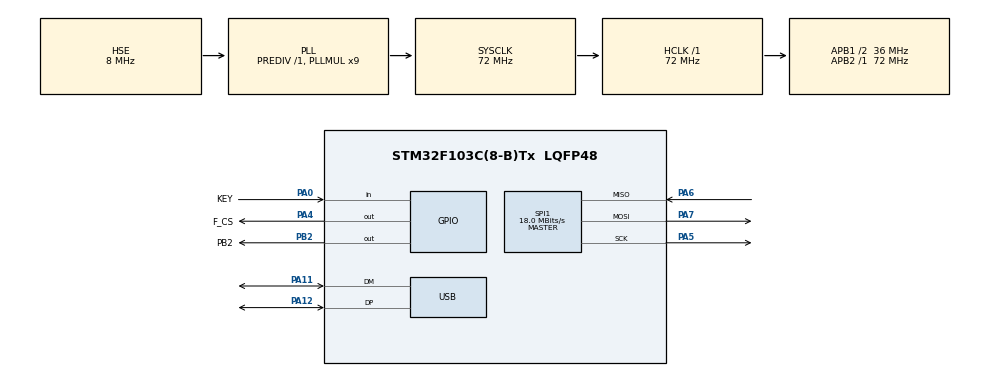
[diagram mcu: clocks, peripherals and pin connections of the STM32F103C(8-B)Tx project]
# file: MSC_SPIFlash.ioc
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Mcu.Family=STM32F1
Mcu.Name=STM32F103C(8-B)Tx
Mcu.Package=LQFP48
NVIC.PriorityGroup=NVIC_PRIORITYGROUP_4
NVIC.SPI1_IRQn=true\:0\:0\:false\:false\:true\:true\:true
NVIC.USB_HP_CAN1_TX_IRQn=true\:0\:0\:false\:false\:true\:true\:true
NVIC.USB_LP_CAN1_RX0_IRQn=true\:0\:0\:false\:false\:true\:false\:true
PA0-WKUP.GPIO_Label=KEY
PA0-WKUP.GPIO_PuPd=GPIO_PULLDOWN
PA0-WKUP.Signal=GPIO_Input
PA11.Mode=Device
PA11.Signal=USB_DM
PA12.Mode=Device
PA12.Signal=USB_DP
PA13.Mode=Serial_Wire
PA13.Signal=SYS_JTMS-SWDIO
PA14.Mode=Serial_Wire
PA14.Signal=SYS_JTCK-SWCLK
PA4.GPIO_Label=F_CS
PA4.GPIO_Speed=GPIO_SPEED_FREQ_HIGH
PA4.PinState=GPIO_PIN_SET
PA4.Signal=GPIO_Output
PA5.Mode=Full_Duplex_Master
PA5.Signal=SPI1_SCK
PA6.Mode=Full_Duplex_Master
PA6.Signal=SPI1_MISO
PA7.Mode=Full_Duplex_Master
PA7.Signal=SPI1_MOSI
PB2.GPIO_Label=PB2
PB2.Signal=GPIO_Output
PD0-OSC_IN.Mode=HSE-External-Oscillator
PD0-OSC_IN.Signal=RCC_OSC_IN
PD1-OSC_OUT.Mode=HSE-External-Oscillator
PD1-OSC_OUT.Signal=RCC_OSC_OUT
ProjectManager.HeapSize=0x800
ProjectManager.StackSize=0x400
ProjectManager.TargetToolchain=MDK-ARM V5.27
RCC.AHBFreq_Value=72000000
RCC.APB1CLKDivider=RCC_HCLK_DIV2
RCC.APB1Freq_Value=36000000
RCC.APB1TimFreq_Value=72000000
RCC.APB2Freq_Value=72000000
RCC.APB2TimFreq_Value=72000000
RCC.HCLKFreq_Value=72000000
RCC.PLLMUL=RCC_PLL_MUL9
RCC.PLLSourceVirtual=RCC_PLLSOURCE_HSE
RCC.SYSCLKFreq_VALUE=72000000
RCC.SYSCLKSource=RCC_SYSCLKSOURCE_PLLCLK
RCC.USBFreq_Value=48000000
RCC.USBPrescaler=RCC_USBCLKSOURCE_PLL_DIV1_5
SPI1.BaudRatePrescaler=SPI_BAUDRATEPRESCALER_4
SPI1.CalculateBaudRate=18.0 MBits/s
SPI1.Direction=SPI_DIRECTION_2LINES
SPI1.Mode=SPI_MODE_MASTER
SPI1.VirtualType=VM_MASTER
USB_DEVICE.CLASS_NAME_FS=MSC
USB_DEVICE.MSC_MEDIA_PACKET=4096
USB_DEVICE.VirtualMode=Msc
USB_DEVICE.VirtualModeFS=Msc_FS
VP_USB_DEVICE_VS_USB_DEVICE_MSC_FS.Mode=MSC_FS
board=custom

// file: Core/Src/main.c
/* USER CODE BEGIN Header */
/**
  ******************************************************************************
  * @file           : main.c
  * @brief          : Main program body
  ******************************************************************************
  * @attention
  *
  * <h2><center>&copy; Copyright (c) 2020 STMicroelectronics.
  * All rights reserved.</center></h2>
  *
  * This software component is licensed by ST under Ultimate Liberty license
  * SLA0044, the "License"; You may not use this file except in compliance with
  * the License. You may obtain a copy of the License at:
  *                             www.st.com/SLA0044
  *
  ******************************************************************************
  */
/* USER CODE END Header */

#include "main.h"
#include "spi.h"
#include "usb_device.h"
#include "gpio.h"

/* USER CODE BEGIN Includes */
#include "w25qxx.h"
/* USER CODE END Includes */

void SystemClock_Config(void);

/* USER CODE BEGIN 0 */
 /*
  *power by WeAct Studio
  *The board with `WeAct` Logo && `version number` is our board, quality guarantee.
  *For more information please visit: https://github.com/WeActStudio/BluePill-Plus.git
  *更多信息请访问：https://gitee.com/WeActStudio/BluePill-Plus
  */
/* USER CODE END 0 */

int main(void)
{

  /* MCU Configuration--------------------------------------------------------*/

  /* Reset of all peripherals, Initializes the Flash interface and the Systick. */
  HAL_Init();

  /* Configure the system clock */
  SystemClock_Config();

  /* Initialize all configured peripherals */
  MX_GPIO_Init();
  MX_SPI1_Init();
  MX_USB_DEVICE_Init();

  /* Infinite loop */
  while (1)
  {

    /* USER CODE BEGIN 3 */
		HAL_GPIO_WritePin(PB2_GPIO_Port,PB2_Pin,GPIO_PIN_SET);
		HAL_Delay(5);
		HAL_GPIO_WritePin(PB2_GPIO_Port,PB2_Pin,GPIO_PIN_RESET);
		HAL_Delay(500);
  }
  /* USER CODE END 3 */
}

void SystemClock_Config(void)
{
  RCC_OscInitTypeDef RCC_OscInitStruct = {0};
  RCC_ClkInitTypeDef RCC_ClkInitStruct = {0};
  RCC_PeriphCLKInitTypeDef PeriphClkInit = {0};

  /** Initializes the CPU, AHB and APB busses clocks
  */
  RCC_OscInitStruct.OscillatorType = RCC_OSCILLATORTYPE_HSE;
  RCC_OscInitStruct.HSEState = RCC_HSE_ON;
  RCC_OscInitStruct.HSEPredivValue = RCC_HSE_PREDIV_DIV1;
  RCC_OscInitStruct.HSIState = RCC_HSI_ON;
  RCC_OscInitStruct.PLL.PLLState = RCC_PLL_ON;
  RCC_OscInitStruct.PLL.PLLSource = RCC_PLLSOURCE_HSE;
  RCC_OscInitStruct.PLL.PLLMUL = RCC_PLL_MUL9;
  if (HAL_RCC_OscConfig(&RCC_OscInitStruct) != HAL_OK)
  {
    Error_Handler();
  }
  /** Initializes the CPU, AHB and APB busses clocks
  */
  RCC_ClkInitStruct.ClockType = RCC_CLOCKTYPE_HCLK|RCC_CLOCKTYPE_SYSCLK
                              |RCC_CLOCKTYPE_PCLK1|RCC_CLOCKTYPE_PCLK2;
  RCC_ClkInitStruct.SYSCLKSource = RCC_SYSCLKSOURCE_PLLCLK;
  RCC_ClkInitStruct.AHBCLKDivider = RCC_SYSCLK_DIV1;
  RCC_ClkInitStruct.APB1CLKDivider = RCC_HCLK_DIV2;
  RCC_ClkInitStruct.APB2CLKDivider = RCC_HCLK_DIV1;

  if (HAL_RCC_ClockConfig(&RCC_ClkInitStruct, FLASH_LATENCY_2) != HAL_OK)
  {
    Error_Handler();
  }
  PeriphClkInit.PeriphClockSelection = RCC_PERIPHCLK_USB;
  PeriphClkInit.UsbClockSelection = RCC_USBCLKSOURCE_PLL_DIV1_5;
  if (HAL_RCCEx_PeriphCLKConfig(&PeriphClkInit) != HAL_OK)
  {
    Error_Handler();
  }
}

void Error_Handler(void)
{
}

/************************ (C) COPYRIGHT STMicroelectronics *****END OF FILE****/
